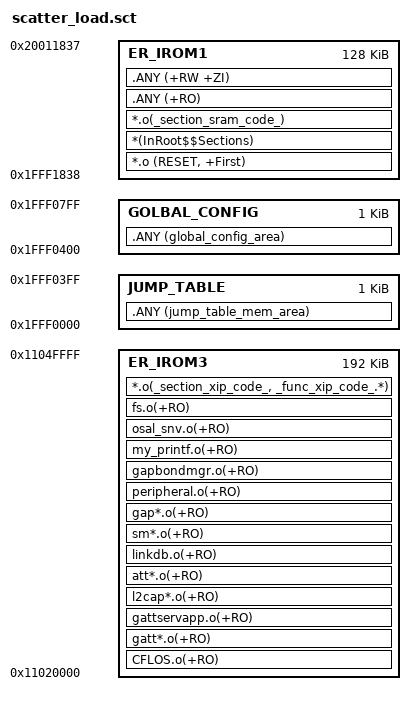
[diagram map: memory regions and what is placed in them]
; *************************************************************
; *** Scatter-Loading Description File generated by uVision ***
; *************************************************************

LR_IROM1 0x1fff1838 0x020000 {  ; load region size_region 0x10000 0x0B7C8
ER_IROM1 0x1fff1838 0x020000  {  ; load address = execution address 0x10000
  *.o (RESET, +First)
  *(InRoot$$Sections)
  ;*.o(_section_standby_code_)
  *.o(_section_sram_code_)
  .ANY (+RO)  
  .ANY (+RW +ZI)
 }
}
LR_IROM4  0x1fff0000 0x00800 {
  JUMP_TABLE 0x1fff0000 0x00400  {
   .ANY (jump_table_mem_area) 
	
  }
  GOLBAL_CONFIG 0x1fff0400 0x00400  {
   .ANY (global_config_area) 
	
  }  
 } 
LR_IROM3  0x11020000 0x030000 {
  ER_IROM3 0x11020000 0x030000  {  ; load address = execution address
   ;libethermind_mesh_models.o(+RO) 
   ;libethermind_utils.o(+RO) 
   ;libethermind_mesh_core.o(+RO) 
   ;appl_*.o(+RO)
   ;;;;;
   ;devinfoservice.o(+RO)
   CFLOS.o(+RO)
   gatt*.o(+RO)
   gattservapp.o(+RO)
   l2cap*.o(+RO)
   att*.o(+RO)
   linkdb.o(+RO)
   sm*.o(+RO)
   gap*.o(+RO)
   peripheral.o(+RO)
   ;hidkbd.o(+RO)
   ;hiddev.o(+RO)
   ;hidkbdservice.o(+RO)
   ;battservice.o(+RO)
   gapbondmgr.o(+RO)
   ;log.o(+RO)
   my_printf.o(+RO)
   osal_snv.o(+RO)
   fs.o(+RO)
   *.o(_section_xip_code_, _func_xip_code_.*)
  }
 }  



